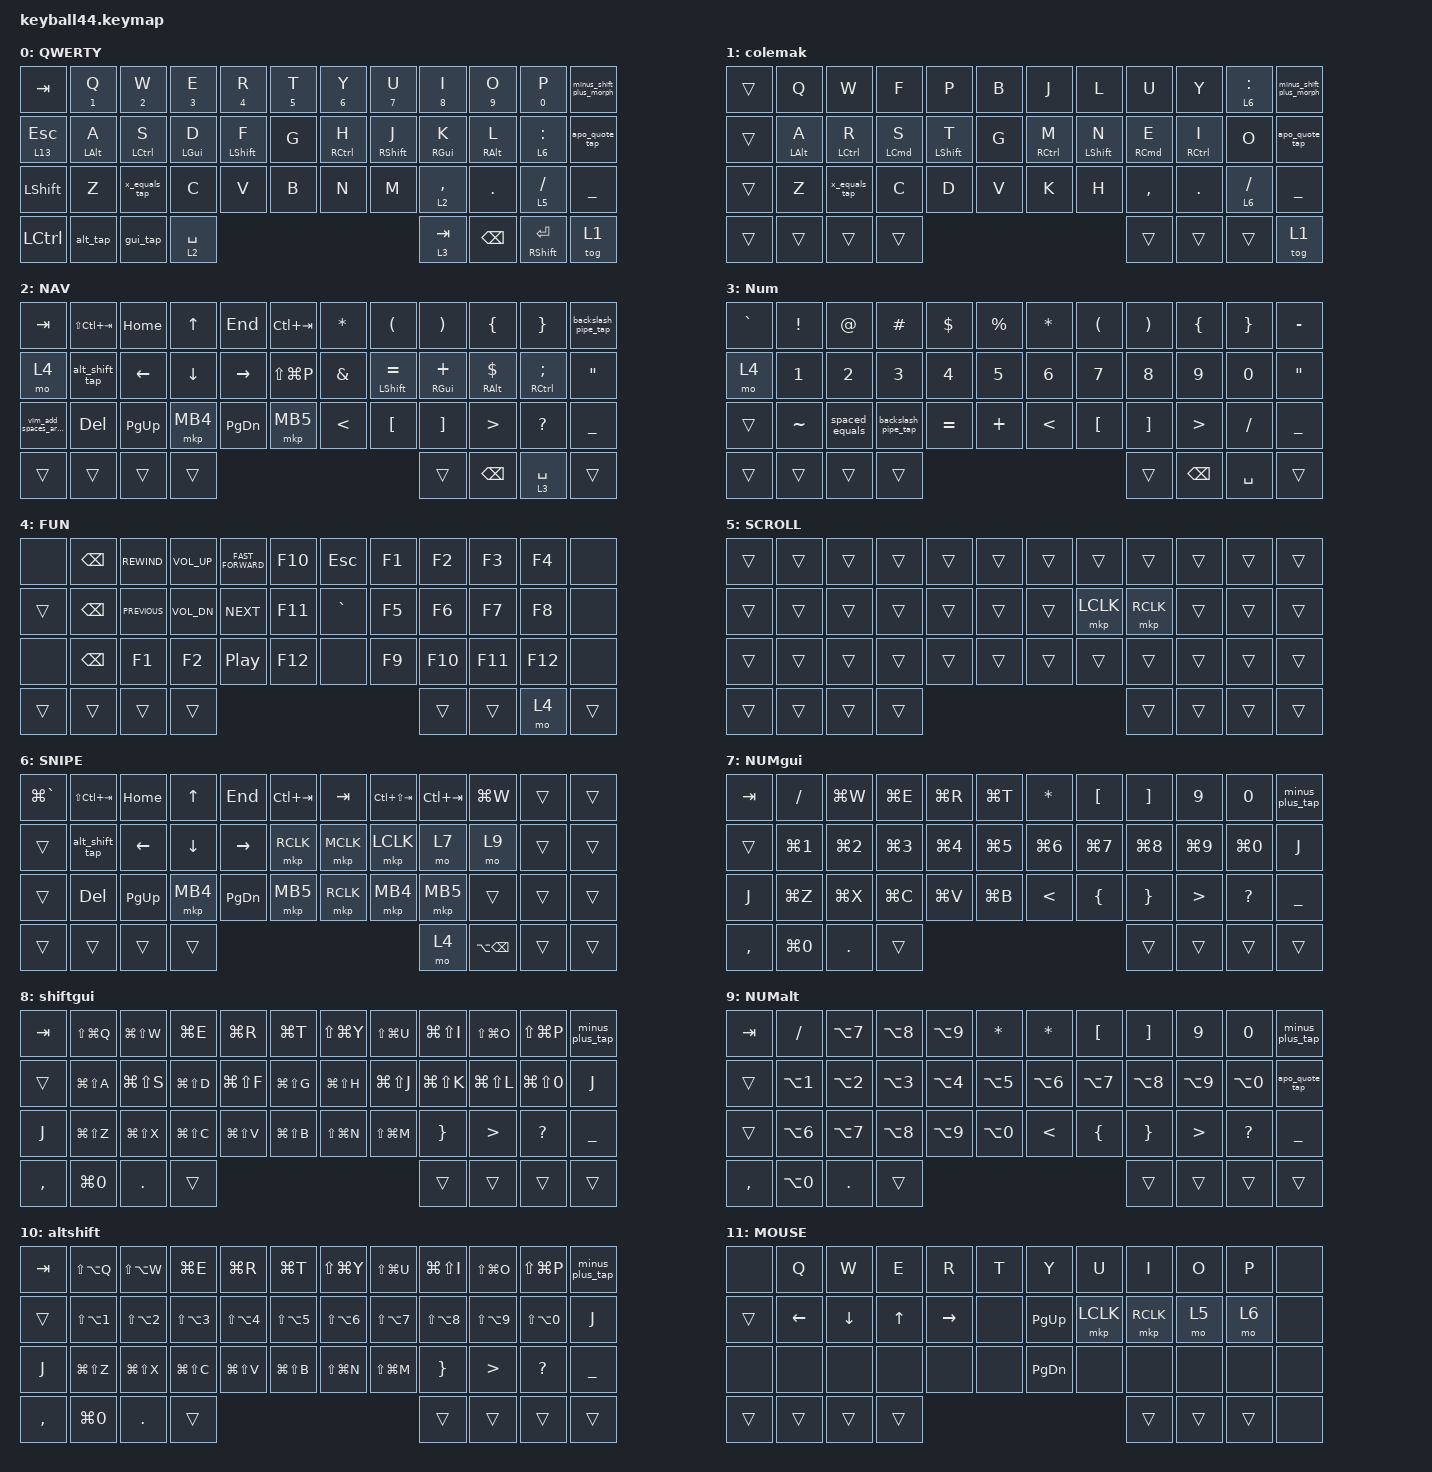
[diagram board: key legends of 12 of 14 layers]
#define DEFAULT 0
#define NUM     1
#define SYM     2
#define FUN     3
#define MOUSE   4
#define SCROLL  5
#define SNIPE   6

#include <behaviors/mouse_keys.dtsi>
#include <dt-bindings/zmk/mouse.h>
#include <behaviors.dtsi>
#include <dt-bindings/zmk/keys.h>
#include <dt-bindings/zmk/pointing.h>

&lt {
    tapping-term-ms = <240>;
    flavor = "balanced";
    quick-tap-ms = <150>;
};

&mt {
    tapping-term-ms = <200>;
    flavor = "tap-preferred";
    quick-tap-ms = <150>;
};

&caps_word { continue-list = <UNDERSCORE MINUS>; };

/ {
    // custom shift using mod-morph 

    behaviors {
        cmqus: comma_question {
            compatible = "zmk,behavior-mod-morph";
            label = "COMMA_QUESTION";
            #binding-cells = <0>;
            bindings = <&kp COMMA>, <&kp QUESTION>;

            mods = <(MOD_LSFT|MOD_RSFT)>;
        };

        dtsmi: dot_semi {
            compatible = "zmk,behavior-mod-morph";
            label = "DOT_SEMI";
            #binding-cells = <0>;
            bindings = <&kp DOT>, <&kp SEMI>;

            mods = <(MOD_LSFT|MOD_RSFT)>;
        };

        apo_quote_tap: apo_quote_tap {
            compatible = "zmk,behavior-tap-dance";
            label = "APO_QUOTE_TAP";
            #binding-cells = <0>;
            bindings = <&kp APOS>, <&kp DOUBLE_QUOTES>;

            tapping-term-ms = <250>;
        };

        minus_plus_tap: minus_plus_tap {
            compatible = "zmk,behavior-tap-dance";
            label = "MINUS_PLUS_TAP";
            #binding-cells = <0>;
            bindings = <&kp MINUS>, <&kp PLUS>;

            tapping-term-ms = <250>;
        };

        x_equals_tap: x_equals_tap {
            compatible = "zmk,behavior-tap-dance";
            label = "X_EQUALS_TAP";
            #binding-cells = <0>;
            bindings = <&kp X>, <&kp EQUAL>;

            tapping-term-ms = <225>;
        };

        gui_tap: gui_tap {
            compatible = "zmk,behavior-tap-dance";
            label = "GUI_TAP";
            #binding-cells = <0>;
            bindings = <&kp LEFT_GUI>, <&sl 7>;

            tapping-term-ms = <250>;
        };

        alt_tap: alt_tap {
            compatible = "zmk,behavior-tap-dance";
            label = "ALT_TAP";
            #binding-cells = <0>;
            bindings = <&kp LEFT_ALT>, <&sl 9>;

            tapping-term-ms = <250>;
        };

        hold_preferred: hold_preferred {
            compatible = "zmk,behavior-hold-tap";
            label = "HOLD_PREFERRED";
            bindings = <&mo>, <&kp>;

            #binding-cells = <2>;
            tapping-term-ms = <150>;
        };

        balanced_modtap: balanced_modtap {
            compatible = "zmk,behavior-hold-tap";
            label = "BALANCED_MODTAP";
            bindings = <&mo>, <&kp>;

            #binding-cells = <2>;
            tapping-term-ms = <150>;
            require-prior-idle-ms = <50>;
            flavor = "balanced";
        };

        Hold_key_sticky_layer: Hold_key_sticky_layer {
            compatible = "zmk,behavior-hold-tap";
            label = "HOLD_KEY_STICKY_LAYER";
            bindings = <&kp>, <&sl>;

            #binding-cells = <2>;
            tapping-term-ms = <150>;
        };

        Hold_or_tap_layer: Hold_or_tap_layer {
            compatible = "zmk,behavior-hold-tap";
            label = "HOLD_OR_TAP_LAYER";
            bindings = <&mo>, <&mo>;

            #binding-cells = <2>;
            tapping-term-ms = <150>;
        };

        backslash_pipe_tap: backslash_pipe_tap {
            compatible = "zmk,behavior-tap-dance";
            label = "BACKSLASH_PIPE_TAP";
            #binding-cells = <0>;
            bindings = <&kp BACKSLASH>, <&kp PIPE>;

            tapping-term-ms = <225>;
        };

        hm_l: homerow_mods_left {
            compatible = "zmk,behavior-hold-tap";
            #binding-cells = <2>;
            bindings = <&kp>, <&kp>;

            flavor = "balanced";
            tapping-term-ms = <175>; // Use to be HM_TAPPING_TERM
            quick-tap-ms = <175>;                // repeat on tap-into-hold
            require-prior-idle-ms = <100>; // Used to be HM_PRIOR_IDLE
            hold-trigger-on-release;
            hold-trigger-key-positions = <6 7 8 9 10 11 18 19 20 21 22 23 30 31 32 33 34 35 43 41 42>;
        };

        hm_r: homerow_mods_right {
            compatible = "zmk,behavior-hold-tap";
            #binding-cells = <2>;
            bindings = <&kp>, <&kp>;

            flavor = "balanced";
            tapping-term-ms = <175>;
            quick-tap-ms = <175>;
            require-prior-idle-ms = <100>;
            hold-trigger-on-release;
            hold-trigger-key-positions = <0 1 2 5 12 13 14 15 16 17 24 25 26 27 28 29 36 37 38 39 40 4 3>;
        };

        // Positional Homerow mods for shift
        // Use faster tapping term and disable some features that may
        // cause false negatives.

        hm_shift_l: hm_shift_l {
            compatible = "zmk,behavior-hold-tap";
            #binding-cells = <2>;
            bindings = <&kp>, <&kp>;

            flavor = "balanced";
            tapping-term-ms = <175>;
            quick-tap-ms = <175>;
            require-prior-idle-ms = <100>;

            // hold-trigger-on-release;

            hold-trigger-key-positions = <6 7 8 9 10 11 18 19 20 21 22 23 30 31 32 33 34 35 43 41 42>;
        };

        hm_shift_r: hm_shift_r {
            compatible = "zmk,behavior-hold-tap";
            #binding-cells = <2>;
            bindings = <&kp>, <&kp>;

            flavor = "balanced";
            tapping-term-ms = <175>;
            quick-tap-ms = <175>;
            require-prior-idle-ms = <100>;

            // hold-trigger-on-release;

            hold-trigger-key-positions = <0 1 2 3 4 5 12 13 14 15 16 17 24 25 26 27 28 29 36 37 38 39 40>;
        };

        /*
         * Non-Positional Homerow Mods
         * Used for &mm_grescm_gui behavior on left hand.
         *
         * Usage: &hm LSHFT T
         * Tap: T
         * Tap-Tap-Hold: Repeat T
         * Hold: LSHIFT
         */

        hm: homerow_mods {
            compatible = "zmk,behavior-hold-tap";
            #binding-cells = <2>;
            bindings = <&kp>, <&kp>;

            flavor = "balanced";
            tapping-term-ms = <175>;
            quick-tap-ms = <200>;
        };

        minus_shift_plus_morph: minus_shift_plus_morph {
            compatible = "zmk,behavior-mod-morph";
            label = "MINUS_SHIFT_PLUS_MORPH";
            bindings = <&kp MINUS>, <&kp PLUS>;

            #binding-cells = <0>;
            mods = <(MOD_LSFT|MOD_RSFT)>;
        };

        alt_shift_tap: alt_shift_tap {
            compatible = "zmk,behavior-tap-dance";
            label = "ALT_SHIFT_TAP";
            #binding-cells = <0>;
            bindings = <&kp LEFT_ALT>, <&kp LS(LEFT_ALT)>;
        };

        hold_preferred_kp_kp: hold_preferred_kp_kp {
            compatible = "zmk,behavior-hold-tap";
            label = "HOLD_PREFERRED_KP_KP";
            bindings = <&kp>, <&kp>;

            #binding-cells = <2>;
            tapping-term-ms = <150>;
        };

        num_hold: num_hold {
            compatible = "zmk,behavior-hold-tap";
            label = "NUM_HOLD";
            bindings = <&kp>, <&kp>;

            #binding-cells = <2>;
            tapping-term-ms = <200>;
            flavor = "tap-preferred";
        };
    };

    combos {
        compatible = "zmk,combos";

        semicolon_combo {
            bindings = <&kp SEMI>;
            key-positions = <33 32>;
        };

        scroll {
            bindings = <&mo 5>;
            key-positions = <19 20 21>;
        };

        esc {
            bindings = <&kp ESCAPE>;
            key-positions = <15 16 14>;
            timeout-ms = <150>;
            require-prior-idle-ms = <50>;
        };

        numlock {
            bindings = <&tog 4>;
            key-positions = <>;
        };

        wa {
            bindings = <&kp LG(LS(P))>;
            key-positions = <9 10 11>;
        };

        caps {
            bindings = <&kp CAPS>;
            key-positions = <7 8 9>;
        };

        console {
            bindings = <&kp LG(GRAVE)>;
            key-positions = <0 1>;
        };

        equals {
            bindings = <&kp EQUAL>;
            key-positions = <>;
        };

        spaces_around_insert {
            bindings = <&none>;
            key-positions = <28 29>;
        };
    };

    macros {
        vim_add_spaces_around: add_spaces_around_a_character {
            compatible = "zmk,behavior-macro";
            #binding-cells = <0>;
            bindings = <&kp I &kp SPACE &kp RIGHT_ARROW &kp SPACE &kp ESCAPE>;
            label = "ADD_SPACES_AROUND_A_CHARACTER";
        };

        vim_spaces_around_insert: vim_spaces_around_insert {
            compatible = "zmk,behavior-macro";
            #binding-cells = <0>;
            bindings = <&kp LEFT &kp SPACE &kp RIGHT_ARROW &kp SPACE>;
            label = "VIM_SPACES_AROUND_INSERT";
        };

        spaced_equals: spaced_equals {
            compatible = "zmk,behavior-macro";
            #binding-cells = <0>;
            bindings = <&kp SPACE &kp EQUAL &kp SPACE>;
            label = "SPACED_EQUALS";
        };

        spaced_plus: spaced_plus {
            compatible = "zmk,behavior-macro";
            #binding-cells = <0>;
            bindings = <&kp SPACE &kp PLUS &kp SPACE>;
            label = "SPACED_PLUS";
        };
    };

    keymap {
        compatible = "zmk,keymap";

        default_layer {
            label = "QWERTY";
            bindings = <
&kp TAB                    &num_hold NUMBER_1 Q  &num_hold NUMBER_2 W  &num_hold NUMBER_3 E  &num_hold NUMBER_4 R      &num_hold N5 T                     &num_hold NUMBER_6 Y                     &num_hold N7 U             &num_hold N8 I           &num_hold N9 O     &num_hold N0 P           &minus_shift_plus_morph
&hold_preferred 13 ESCAPE  &hm_l LEFT_ALT A      &hm_l LEFT_CONTROL S  &hm_l LEFT_GUI D      &hm_shift_l LEFT_SHIFT F  &kp G                              &hm_r RCTRL H                            &hm_shift_r RIGHT_SHIFT J  &hm_r RIGHT_GUI K        &hm_r RIGHT_ALT L  &hold_preferred 6 COLON  &apo_quote_tap
&kp LEFT_SHIFT             &kp Z                 &x_equals_tap         &kp C                 &kp V                     &kp B                              &kp N                                    &kp M                      &hold_preferred 2 COMMA  &kp DOT            &lt 5 SLASH              &kp UNDER
&kp LEFT_CONTROL           &alt_tap              &gui_tap              &lt 2 SPACE           &hold_preferred 3 TAB                         &kp BACKSPACE  &hold_preferred_kp_kp RIGHT_SHIFT ENTER                                                                                                  &tog 1
            >;
        };

        colemak {
            label = "colemak";
            bindings = <
&trans  &kp Q             &kp W          &kp F                 &kp P               &kp B              &kp J          &kp L               &kp U                  &kp Y          &balanced_modtap 6 COLON  &minus_shift_plus_morph
&trans  &hm_l LEFT_ALT A  &hm_l LCTRL R  &hm_l LEFT_COMMAND S  &hm_l LEFT_SHIFT T  &kp G              &hm_r RCTRL M  &hm_r LEFT_SHIFT N  &hm_r RIGHT_COMMAND E  &hm_r RCTRL I  &kp O                     &apo_quote_tap
&trans  &kp Z             &x_equals_tap  &kp C                 &kp D               &kp V              &kp K          &kp H               &kp COMMA              &kp DOT        &lt 6 SLASH               &kp UNDER
&trans  &trans            &trans         &trans                &trans                         &trans  &trans                                                                                             &tog 1
            >;
        };

        symbol_nav {
            label = "NAV";
            bindings = <
&kp TAB                 &kp LS(LC(TAB))  &kp HOME   &kp UP          &kp END        &kp LC(TAB)                       &kp ASTERISK             &kp LEFT_PARENTHESIS    &kp RIGHT_PARENTHESIS  &kp LEFT_BRACE          &kp RIGHT_BRACE   &backslash_pipe_tap
&mo 4                   &alt_shift_tap   &kp LEFT   &kp DOWN_ARROW  &kp RIGHT      &kp LS(LG(P))                     &kp AMPS                 &hm_r LEFT_SHIFT EQUAL  &hm_r RIGHT_GUI PLUS   &hm_r RIGHT_ALT DOLLAR  &hm_r RCTRL SEMI  &kp DOUBLE_QUOTES
&vim_add_spaces_around  &kp DELETE       &kp PG_UP  &mkp MB4        &kp PAGE_DOWN  &mkp MB5                          &kp LESS_THAN            &kp LEFT_BRACKET        &kp RIGHT_BRACKET      &kp GREATER_THAN        &kp QMARK         &kp UNDER
&trans                  &trans           &trans     &trans          &trans                            &kp BACKSPACE  &hold_preferred 3 SPACE                                                                                           &trans
            >;
        };

        num_homerow {
            label = "Num";
            bindings = <
&kp GRAVE  &kp EXCL   &kp AT          &kp HASH             &kp DOLLAR  &kp PERCENT                     &kp ASTERISK   &kp LEFT_PARENTHESIS  &kp RIGHT_PARENTHESIS  &kp LEFT_BRACE    &kp RIGHT_BRACE  &kp MINUS
&mo 4      &kp N1     &kp N2          &kp N3               &kp N4      &kp N5                          &kp N6         &kp N7                &kp N8                 &kp N9            &kp N0           &kp DOUBLE_QUOTES
&trans     &kp TILDE  &spaced_equals  &backslash_pipe_tap  &kp EQUAL   &kp PLUS                        &kp LESS_THAN  &kp LEFT_BRACKET      &kp RIGHT_BRACKET      &kp GREATER_THAN  &kp SLASH        &kp UNDER
&trans     &trans     &trans          &trans               &trans                       &kp BACKSPACE  &kp SPACE                                                                                      &trans
            >;
        };

        function_layer {
            label = "FUN";
            bindings = <
&none   &kp BSPC  &kp C_REWIND    &kp C_VOL_UP  &kp C_FAST_FORWARD  &kp F10              &kp ESC    &kp F1  &kp F2   &kp F3   &kp F4   &none
&trans  &kp BSPC  &kp C_PREVIOUS  &kp C_VOL_DN  &kp C_NEXT          &kp F11              &kp GRAVE  &kp F5  &kp F6   &kp F7   &kp F8   &none
&none   &kp BSPC  &kp F1          &kp F2        &kp C_PLAY_PAUSE    &kp F12              &none      &kp F9  &kp F10  &kp F11  &kp F12  &none
&trans  &trans    &trans          &trans        &trans                           &trans  &mo 4                                         &trans
            >;
        };

        scroll_layer {
            label = "SCROLL";
            bindings = <
&trans  &trans  &trans  &trans  &trans  &trans              &trans  &trans     &trans     &trans  &trans  &trans
&trans  &trans  &trans  &trans  &trans  &trans              &trans  &mkp LCLK  &mkp RCLK  &trans  &trans  &trans
&trans  &trans  &trans  &trans  &trans  &trans              &trans  &trans     &trans     &trans  &trans  &trans
&trans  &trans  &trans  &trans  &trans              &trans  &trans                                        &trans
            >;
        };

        snipe_layer {
            label = "SNIPE";
            bindings = <
&kp LG(GRAVE)  &kp LS(LC(TAB))  &kp HOME   &kp UP_ARROW  &kp END    &kp LC(TAB)                         &kp TAB    &kp LC(LS(TAB))  &kp LC(TAB)  &kp LG(W)  &trans  &trans
&trans         &alt_shift_tap   &kp LEFT   &kp DOWN      &kp RIGHT  &mkp RCLK                           &mkp MCLK  &mkp LCLK        &mo 7        &mo 9      &trans  &trans
&trans         &kp DELETE       &kp PG_UP  &mkp MB4      &kp PG_DN  &mkp MB5                            &mkp RCLK  &mkp MB4         &mkp MB5     &trans     &trans  &trans
&trans         &trans           &trans     &trans        &mo 4                       &kp LA(BACKSPACE)  &trans                                                      &trans
            >;
        };

        numgui {
            label = "NUMgui";
            bindings = <
&kp TAB    &kp SLASH   &kp LG(W)   &kp LG(E)   &kp LG(R)   &kp LG(T)               &kp ASTERISK   &kp LBKT        &kp RBKT         &kp NUMBER_9      &kp NUMBER_0  &minus_plus_tap
&trans     &kp LG(N1)  &kp LG(N2)  &kp LG(N3)  &kp LG(N4)  &kp LG(N5)              &kp LG(N6)     &kp LG(N7)      &kp LG(N8)       &kp LG(N9)        &kp LG(N0)    &kp J
&kp J      &kp LG(Z)   &kp LG(X)   &kp LG(C)   &kp LG(V)   &kp LG(B)               &kp LESS_THAN  &kp LEFT_BRACE  &kp RIGHT_BRACE  &kp GREATER_THAN  &kp QMARK     &kp UNDER
&kp COMMA  &kp LG(N0)  &kp DOT     &trans      &trans                      &trans  &trans                                                                          &trans
            >;
        };

        shiftgui {
            label = "shiftgui";
            bindings = <
&kp TAB    &kp LS(LG(Q))  &kp LG(LS(W))  &kp LG(E)      &kp LG(R)      &kp LG(T)                  &kp LS(LG(Y))  &kp LS(LG(U))  &kp LG(LS(I))    &kp LS(LG(O))     &kp LS(LG(P))   &minus_plus_tap
&trans     &kp LG(LS(A))  &kp LG(LS(S))  &kp LG(LS(D))  &kp LG(LS(F))  &kp LG(LS(G))              &kp LG(LS(H))  &kp LG(LS(J))  &kp LG(LS(K))    &kp LG(LS(L))     &kp LG(LS(N0))  &kp J
&kp J      &kp LG(LS(Z))  &kp LG(LS(X))  &kp LG(LS(C))  &kp LG(LS(V))  &kp LG(LS(B))              &kp LS(LG(N))  &kp LS(LG(M))  &kp RIGHT_BRACE  &kp GREATER_THAN  &kp QMARK       &kp UNDER
&kp COMMA  &kp LG(N0)     &kp DOT        &trans         &trans                            &trans  &trans                                                                           &trans
            >;
        };

        numalt {
            label = "NUMalt";
            bindings = <
&kp TAB    &kp SLASH         &kp LA(N7)  &kp LA(N8)  &kp LA(N9)  &kp ASTERISK              &kp ASTERISK   &kp LBKT        &kp RBKT         &kp NUMBER_9      &kp NUMBER_0  &minus_plus_tap
&trans     &kp LA(N1)        &kp LA(N2)  &kp LA(N3)  &kp LA(N4)  &kp LA(N5)                &kp LA(N6)     &kp LA(N7)      &kp LA(N8)       &kp LA(N9)        &kp LA(N0)    &apo_quote_tap
&trans     &kp LA(NUMBER_6)  &kp LA(N7)  &kp LA(N8)  &kp LA(N9)  &kp LA(N0)                &kp LESS_THAN  &kp LEFT_BRACE  &kp RIGHT_BRACE  &kp GREATER_THAN  &kp QMARK     &kp UNDER
&kp COMMA  &kp LA(N0)        &kp DOT     &trans      &trans                        &trans  &trans                                                                          &trans
            >;
        };

        altshift {
            label = "altshift";
            bindings = <
&kp TAB    &kp LS(LA(Q))         &kp LS(LA(W))         &kp LG(E)             &kp LG(R)             &kp LG(T)                   &kp LS(LG(Y))         &kp LS(LG(U))   &kp LG(LS(I))    &kp LS(LG(O))     &kp LS(LG(P))   &minus_plus_tap
&trans     &kp LS(LA(NUMBER_1))  &kp LS(LA(NUMBER_2))  &kp LS(LA(NUMBER_3))  &kp LS(LA(NUMBER_4))  &kp LS(LA(N5))              &kp LS(LA(NUMBER_6))  &kp LS(LA(N7))  &kp LS(LA(N8))   &kp LS(LA(N9))    &kp LS(LA(N0))  &kp J
&kp J      &kp LG(LS(Z))         &kp LG(LS(X))         &kp LG(LS(C))         &kp LG(LS(V))         &kp LG(LS(B))               &kp LS(LG(N))         &kp LS(LG(M))   &kp RIGHT_BRACE  &kp GREATER_THAN  &kp QMARK       &kp UNDER
&kp COMMA  &kp LG(N0)            &kp DOT               &trans                &trans                                    &trans  &trans                                                                                   &trans
            >;
        };

        mouse_layer {
            label = "MOUSE";
            bindings = <
&none   &kp Q           &kp W           &kp E         &kp R      &kp T              &kp Y          &kp U      &kp I      &kp O  &kp P  &none
&trans  &kp LEFT_ARROW  &kp DOWN_ARROW  &kp UP_ARROW  &kp RIGHT  &none              &kp PAGE_UP    &mkp LCLK  &mkp RCLK  &mo 5  &mo 6  &none
&none   &none           &none           &none         &none      &none              &kp PAGE_DOWN  &none      &none      &none  &none  &none
&trans  &trans          &trans          &trans        &trans                &trans  &trans                                             &none
            >;
        };

        numerical {
            label = "NUM";
            bindings = <
&kp TAB    &kp SLASH     &kp N7   &kp N8  &kp N9  &kp ASTERISK              &kp ASTERISK   &kp LBKT              &kp RBKT               &kp GRAVE         &kp PIPE   &minus_plus_tap
&trans     &kp MINUS     &kp N4   &kp N5  &kp N6  &kp PLUS                  &kp MINUS      &kp LEFT_PARENTHESIS  &kp RIGHT_PARENTHESIS  &kp PERCENT       &kp COLON  &apo_quote_tap
&trans     &kp NUMBER_0  &kp N1   &kp N2  &kp N3  &kp EQUAL                 &kp LESS_THAN  &kp LEFT_BRACE        &kp RIGHT_BRACE        &kp GREATER_THAN  &kp QMARK  &kp UNDER
&kp COMMA  &kp N0        &kp DOT  &trans  &trans                    &trans  &trans                                                                                   &trans
            >;
        };

        l_snipe {
            label = "left_snipe";
            bindings = <
&kp LG(GRAVE)  &kp HOME    &none        &kp END        &kp LC(LS(TAB))  &kp LC(TAB)                         &kp LG(T)  &kp LC(LS(TAB))  &kp LC(TAB)  &kp LG(W)  &trans  &trans
&trans         &none       &none        &none          &mkp LCLK        &mkp RCLK                           &mkp MCLK  &mkp LCLK        &mkp RCLK    &mo 9      &trans  &trans
&trans         &kp DELETE  &kp PAGE_UP  &kp PAGE_DOWN  &mkp MB4         &mkp MB5                            &trans     &mkp MB4         &mkp MB5     &trans     &trans  &trans
&trans         &trans      &trans       &trans         &mo 4                             &kp LA(BACKSPACE)  &trans                                                      &trans
            >;
        };
    };
};
